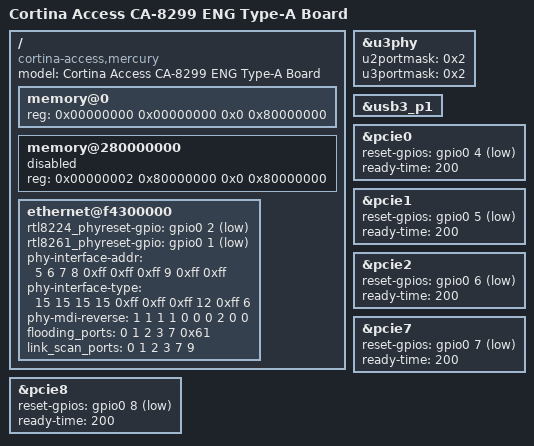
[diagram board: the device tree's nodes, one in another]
/dts-v1/;

#include "ca8299/ca8299-soc.dtsi"
#include "ca-nand.dtsi"
#include <dt-bindings/gpio/gpio.h>
#include "ca8299/ca8299-led.dtsi"
#include "ca8299-eng-voip.dts"

/ {
	model = "Cortina Access CA-8299 ENG Type-A Board";
	compatible = "cortina-access,mercury";
	#address-cells = <2>;
	#size-cells = <2>;

	memory@0 { /* 2GB */
		device_type = "memory";
		reg = <0x00000000 0x00000000 0x0 0x80000000>;
	};
	memory@280000000 { /* 2GB */
		device_type = "memory";
		reg = <0x00000002 0x80000000 0x0 0x80000000>;
		status = "disabled";
	};

	ethernet@f4300000 {
		rtl8224_phyreset-gpio = <&gpio0 2 GPIO_ACTIVE_LOW>;
		rtl8261_phyreset-gpio = <&gpio0 1 GPIO_ACTIVE_LOW>;

		phy-interface-addr = <5 6 7 8 0xff 0xff 0xff 9 0xff 0xff>;
		phy-interface-type = <15 15 15 15 0xff 0xff 0xff 12 0xff 6>;
		phy-mdi-reverse = <1 1 1 1 0 0 0 2 0 0>;
		flooding_ports = <0 1 2 3 7 0x61>;
		link_scan_ports = <0 1 2 3 7 9>;
	};
};

&u3phy {
	u2portmask = <0x2>;
	u3portmask = <0x2>;
	status = "okay";
};

&usb3_p1 {
	status = "okay";
};

&pcie0 {
	status = "okay";
	reset-gpios = <&gpio0 4 GPIO_ACTIVE_LOW>;
	ready-time = /bits/ 16 <200>;
};

&pcie1 {
	status = "okay";
	reset-gpios = <&gpio0 5 GPIO_ACTIVE_LOW>;
	ready-time = /bits/ 16 <200>;
};

&pcie2 {
	status = "okay";
	reset-gpios = <&gpio0 6 GPIO_ACTIVE_LOW>;
	ready-time = /bits/ 16 <200>;
};

&pcie7 {
	status = "okay";
	reset-gpios = <&gpio0 7 GPIO_ACTIVE_LOW>;
	ready-time = /bits/ 16 <200>;
};

&pcie8 {
	status = "okay";
	reset-gpios = <&gpio0 8 GPIO_ACTIVE_LOW>;
	ready-time = /bits/ 16 <200>;
};
